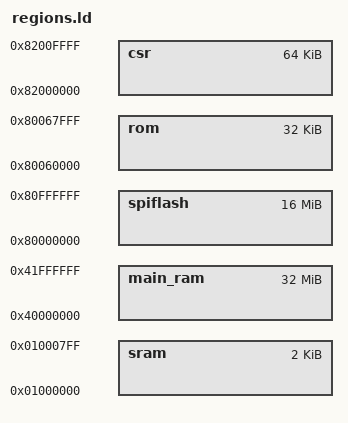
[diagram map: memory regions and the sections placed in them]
MEMORY {
	sram : ORIGIN = 0x01000000, LENGTH = 0x00000800
	spiflash : ORIGIN = 0x80000000, LENGTH = 0x01000000
	rom : ORIGIN = 0x80060000, LENGTH = 0x00008000
	main_ram : ORIGIN = 0x40000000, LENGTH = 0x02000000
	csr : ORIGIN = 0x82000000, LENGTH = 0x00010000
}
